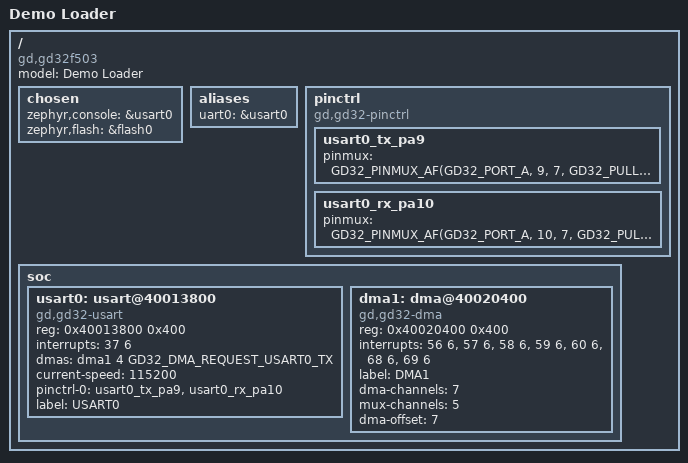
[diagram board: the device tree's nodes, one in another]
/dts-v1/;

#include <arm/gd/gd32f50x.dtsi>
#include <dt-bindings/dma/gd32_dma.h>
#include <dt-bindings/gpio/gpio.h>
#include <dt-bindings/pinctrl/gd32-pinctrl.h>

/ {
    compatible = "gd,gd32f503";
    model = "Demo Loader";

    chosen {
        zephyr,console = &usart0;
        zephyr,flash = &flash0;
    };

    aliases {
        uart0 = &usart0;
    };

    pinctrl: pinctrl {
        compatible = "gd,gd32-pinctrl";

        usart0_tx_pa9: usart0_tx_pa9 {
            pinmux = <GD32_PINMUX_AF(GD32_PORT_A, 9, 7,
                                      GD32_PULL_NONE,
                                      GD32_DRIVE_PUSH_PULL, 3)>;
        };

        usart0_rx_pa10: usart0_rx_pa10 {
            pinmux = <GD32_PINMUX_AF(GD32_PORT_A, 10, 7,
                                      GD32_PULL_UP,
                                      GD32_DRIVE_PUSH_PULL, 3)>;
        };
    };

    soc {
        usart0: usart@40013800 {
            compatible = "gd,gd32-usart";
            reg = <0x40013800 0x400>;
            interrupts = <37 6>;
            interrupt-names = "global";
            dmas = <&dma1 4 GD32_DMA_REQUEST_USART0_TX>;
            dma-names = "tx";
            status = "okay";
            current-speed = <115200>;
            pinctrl-0 = <&usart0_tx_pa9 &usart0_rx_pa10>;
            pinctrl-names = "default";
            label = "USART0";
        };

        dma1: dma@40020400 {
            compatible = "gd,gd32-dma";
            reg = <0x40020400 0x400>;
            interrupts = <56 6>, <57 6>, <58 6>, <59 6>,
                         <60 6>, <68 6>, <69 6>;
            label = "DMA1";
            dma-channels = <7>;
            mux-channels = <5>;
            dma-offset = <7>;
            #dma-cells = <2>;
        };
    };
};
